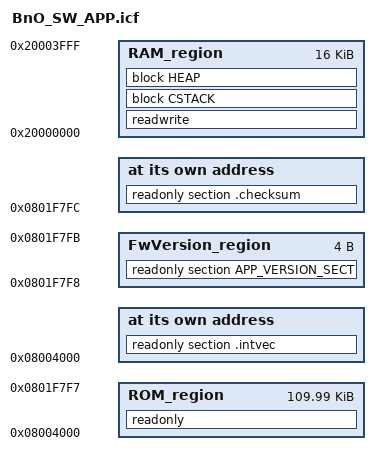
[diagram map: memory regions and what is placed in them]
/*###ICF### Section handled by ICF editor, don't touch! ****/
/*-Editor annotation file-*/
/* IcfEditorFile="$TOOLKIT_DIR$\config\ide\IcfEditor\cortex_v1_0.xml" */

/* When modify memory layout, remember to change
 * 1. link.icf
 * 2. SettingSrv.config, SETT_PAGE_ROM_ADDR
 * 3. Fep_addr.h
 * 4. IAR link setting, checksum address
 */


/*-Specials-*/
define symbol __ICFEDIT_intvec_start__    = 0x08004000;
define symbol __USEREDIT_checksum_start__ = 0x0801F7fc;
/*-Memory Regions-*/
define symbol __ICFEDIT_region_ROM_start__         = 0x08004000;
define symbol __ICFEDIT_region_ROM_end__           = 0x0801F7f7;
define symbol __USEREDIT_region_FW_VERSION_start__ = 0x0801F7f8;
define symbol __USEREDIT_region_FW_VERSION_end__   = 0x0801F7fb;
define symbol __ICFEDIT_region_RAM_start__         = 0x20000000;
define symbol __ICFEDIT_region_RAM_end__           = 0x20003FFF;

/*-Sizes-*/
/* For stack size, we original set to 0xC00, but worry stack overflow occurs, thus set to bigger size now.
 * If RAM is not enough on future, plesae decrase stack size
 */
define symbol __ICFEDIT_size_cstack__ = 0xc00;
define symbol __ICFEDIT_size_heap__   = 0x600;
/**** End of ICF editor section. ###ICF###*/

define memory mem with size = 4G;
define region ROM_region   = mem:[from __ICFEDIT_region_ROM_start__   to __ICFEDIT_region_ROM_end__];
define region RAM_region   = mem:[from __ICFEDIT_region_RAM_start__   to __ICFEDIT_region_RAM_end__];

define region FwVersion_region  = mem:[from __USEREDIT_region_FW_VERSION_start__ to __USEREDIT_region_FW_VERSION_end__];

define block CSTACK    with alignment = 8, size = __ICFEDIT_size_cstack__   { };
define block HEAP      with alignment = 8, size = __ICFEDIT_size_heap__     { };

initialize by copy { readwrite };
do not initialize  { section .noinit };

place at address mem:__ICFEDIT_intvec_start__ { readonly section .intvec };
place at address mem:__USEREDIT_checksum_start__ { readonly section .checksum };

place in ROM_region   { readonly };
place in RAM_region   { readwrite,
                        block CSTACK, block HEAP };
place in FwVersion_region  { readonly section APP_VERSION_SECT };

export symbol __ICFEDIT_region_RAM_start__;
export symbol __ICFEDIT_region_RAM_end__;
